VERSION ""

NS_ :

BS_:

BU_: SIM ADS

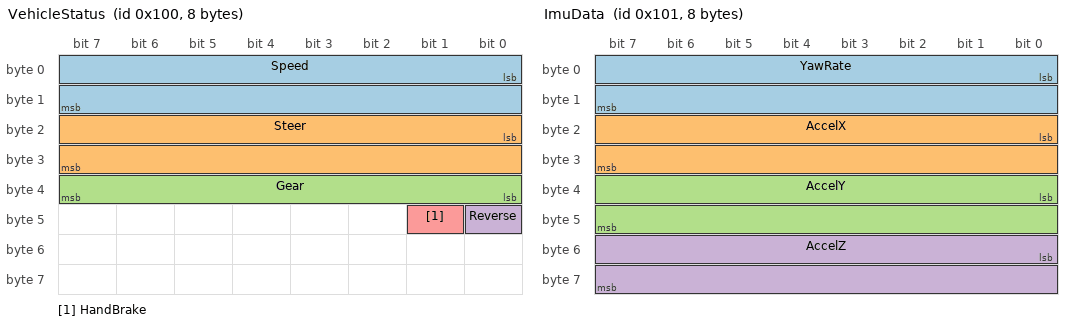
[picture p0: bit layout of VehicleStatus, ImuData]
BO_ 256 VehicleStatus: 8 SIM
 SG_ Speed : 0|16@1- (0.01,0) [-327.68|327.67] "m/s" ADS
 SG_ Steer : 16|16@1- (0.0001,0) [-1|1] "" ADS
 SG_ Gear : 32|8@1- (1,0) [-128|127] "" ADS
 SG_ Reverse : 40|1@1+ (1,0) [0|1] "" ADS
 SG_ HandBrake : 41|1@1+ (1,0) [0|1] "" ADS

BO_ 257 ImuData: 8 SIM
 SG_ YawRate : 0|16@1- (0.0001,0) [-3.2768|3.2767] "rad/s" ADS
 SG_ AccelX : 16|16@1- (0.001,0) [-32.768|32.767] "m/s2" ADS
 SG_ AccelY : 32|16@1- (0.001,0) [-32.768|32.767] "m/s2" ADS
 SG_ AccelZ : 48|16@1- (0.001,0) [-32.768|32.767] "m/s2" ADS

BO_ 260 ImuRates: 8 SIM
 SG_ RollRate : 0|16@1- (0.0001,0) [-3.2768|3.2767] "rad/s" ADS
 SG_ PitchRate : 16|16@1- (0.0001,0) [-3.2768|3.2767] "rad/s" ADS

BO_ 258 GnssPosition: 8 SIM
 SG_ X : 0|32@1- (0.001,0) [-2147483.648|2147483.647] "m" ADS
 SG_ Y : 32|32@1- (0.001,0) [-2147483.648|2147483.647] "m" ADS

BO_ 259 GnssAttitude: 8 SIM
 SG_ Z : 0|32@1- (0.001,0) [-2147483.648|2147483.647] "m" ADS
 SG_ Yaw : 32|16@1- (0.01,0) [-327.68|327.67] "deg" ADS

BO_ 272 PowerMode: 8 SIM
 SG_ Ignition : 0|1@1+ (1,0) [0|1] "" ADS

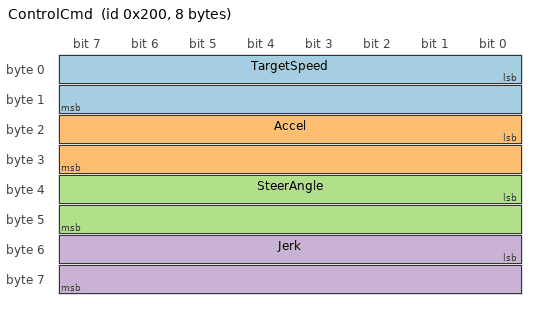
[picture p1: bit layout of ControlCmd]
BO_ 512 ControlCmd: 8 ADS
 SG_ TargetSpeed : 0|16@1- (0.01,0) [-327.68|327.67] "m/s" SIM
 SG_ Accel : 16|16@1- (0.001,0) [-32.768|32.767] "m/s2" SIM
 SG_ SteerAngle : 32|16@1- (0.0001,0) [-3.2768|3.2767] "rad" SIM
 SG_ Jerk : 48|16@1- (0.001,0) [-32.768|32.767] "m/s3" SIM

BO_ 528 EcuStatus: 8 ADS
 SG_ Ready : 0|1@1+ (1,0) [0|1] "" SIM
 SG_ Engaged : 1|1@1+ (1,0) [0|1] "" SIM

CM_ BO_ 256 "Ego state, from scenario-hils signals: Speed = longitudinal_velocity, Steer = CARLA steer (positive right).";
CM_ BO_ 260 "The IMU's roll and pitch rates (vehicle frame, x forward, y left, right-handed), beside ImuData's yaw rate.";
CM_ BO_ 258 "Simulated GNSS: the ego's CARLA x/y (vehicle origin), in metres.";
CM_ BO_ 259 "Simulated GNSS: CARLA z and yaw (degrees, clockwise seen from above).";
CM_ BO_ 512 "Autoware control_cmd as CARLA Ackermann control: TargetSpeed signed (negative = reverse), SteerAngle left-positive tire angle.";
